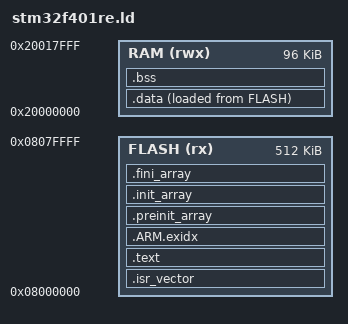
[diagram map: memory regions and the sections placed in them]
/* A minimal linker script for ST's startup_stm32f401xe.s and newlib:
 * 512 KB flash at 0x08000000, 96 KB SRAM at 0x20000000. */
MEMORY
{
    FLASH (rx)  : ORIGIN = 0x08000000, LENGTH = 512K
    RAM   (rwx) : ORIGIN = 0x20000000, LENGTH = 96K
}
ENTRY(Reset_Handler)
_estack = ORIGIN(RAM) + LENGTH(RAM);
SECTIONS
{
    .isr_vector : { KEEP(*(.isr_vector)) } > FLASH
    .text : { *(.text*) *(.rodata*) KEEP(*(.init)) KEEP(*(.fini)) } > FLASH
    .ARM.exidx : { *(.ARM.exidx*) } > FLASH
    .preinit_array : { PROVIDE_HIDDEN(__preinit_array_start = .); KEEP(*(.preinit_array*)); PROVIDE_HIDDEN(__preinit_array_end = .); } > FLASH
    .init_array : { PROVIDE_HIDDEN(__init_array_start = .); KEEP(*(SORT(.init_array.*))); KEEP(*(.init_array*)); PROVIDE_HIDDEN(__init_array_end = .); } > FLASH
    .fini_array : { PROVIDE_HIDDEN(__fini_array_start = .); KEEP(*(.fini_array*)); PROVIDE_HIDDEN(__fini_array_end = .); } > FLASH
    _sidata = LOADADDR(.data);
    .data : { _sdata = .; *(.data*) _edata = .; } > RAM AT> FLASH
    .bss : { _sbss = .; __bss_start__ = .; *(.bss*) *(COMMON) _ebss = .; __bss_end__ = .; } > RAM
    end = .;
}
